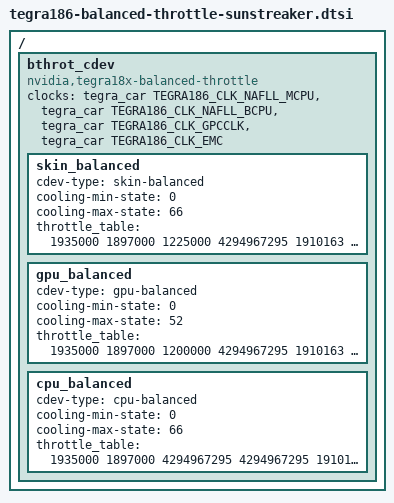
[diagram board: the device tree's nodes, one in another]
/*
 * arch/arm64/boot/dts/tegra186-platforms/tegra186-balanced-throttle-sunstreaker.dtsi
 *
 * Copyright (c) 2016, NVIDIA CORPORATION.  All rights reserved.
 *
 * This program is free software; you can redistribute it and/or modify
 * it under the terms of the GNU General Public License as published by
 * the Free Software Foundation; version 2 of the License.
 *
 * This program is distributed in the hope that it will be useful, but WITHOUT
 * ANY WARRANTY; without even the implied warranty of MERCHANTABILITY or
 * FITNESS FOR A PARTICULAR PURPOSE.  See the GNU General Public License for
 * more details.
 *
 * You should have received a copy of the GNU General Public License along
 * with this program; if not, write to the Free Software Foundation, Inc.,
 * 51 Franklin Street, Fifth Floor, Boston, MA  02110-1301, USA.
 *
 */

/{
	bthrot_cdev {
		compatible = "nvidia,tegra18x-balanced-throttle";
		clocks = <&tegra_car TEGRA186_CLK_NAFLL_MCPU>,
				 <&tegra_car TEGRA186_CLK_NAFLL_BCPU>,
				 <&tegra_car TEGRA186_CLK_GPCCLK>,
				 <&tegra_car TEGRA186_CLK_EMC>;
		clock-names = "mcpu", "bcpu", "gpu", "emc";

		skin_balanced {
			cdev-type = "skin-balanced";
			cooling-min-state = <0>;
			cooling-max-state = <66>;
			#cooling-cells = <2>;
			throttle_table = <
				1935000	1897000	1225000	4294967295
				1910163	1872748	1209454	4294967295
				1885326	1848495	1193908	4294967295
				1860489	1824243	1178362	4294967295
				1835652	1799991	1162815	4294967295
				1810815	1775738	1147269	4294967295
				1785978	1751486	1131723	4294967295
				1761142	1727234	1116177	4294967295
				1736305	1702982	1100631	4294967295
				1711468	1678729	1085085	4294967295
				1686631	1654477	1069538	4294967295
				1661794	1630225	1053992	4294967295
				1636957	1605972	1038446	4294967295
				1612120	1581720	1022900	4294967295
				1587283	1557468	1007354	4294967295
				1562446	1533215	991808	4294967295
				1537609	1508963	976262	4294967295
				1512772	1484711	960715	4294967295
				1487935	1460458	945169	4294967295
				1463098	1436206	929623	4294967295
				1438262	1411954	914077	4294967295
				1413425	1387702	898531	4294967295
				1388588	1363449	882985	4294967295
				1363751	1339197	867438	4294967295
				1338914	1314945	851892	4294967295
				1314077	1290692	836346	4294967295
				1289240	1266440	820800	4294967295
				1264403	1242188	805254	4294967295
				1239566	1217935	789708	4294967295
				1214729	1193683	774162	4294967295
				1189892	1169431	758615	4294967295
				1165055	1145178	743069	4294967295
				1140218	1120926	727523	4294967295
				1115382	1096674	711977	4294967295
				1090545	1072422	696431	4294967295
				1065708	1048169	680885	4294967295
				1040871	1023917	665338	4294967295
				1016034	999665	649792	4294967295
				991197	975412	634246	4294967295
				966360	951160	618700	4294967295
				941523	926908	603154	4294967295
				916686	902655	587608	4294967295
				891849	878403	572062	4294967295
				867012	854151	556515	4294967295
				842175	829898	540969	4294967295
				817338	805646	525423	4294967295
				792502	781394	509877	4294967295
				767665	757142	494331	4294967295
				742828	732889	478785	4294967295
				717991	708637	463238	4294967295
				693154	684385	447692	4294967295
				668317	660132	432146	4294967295
				643480	635880	416600	4294967295
				618643	611628	401054	4294967295
				593806	587375	385508	4294967295
				568969	563123	369962	4294967295
				544132	538871	354415	4294967295
				519295	514618	338869	4294967295
				494458	490366	323323	4294967295
				469622	466114	307777	4294967295
				444785	441862	292231	4294967295
				419948	417609	276685	4294967295
				395111	393357	261138	4294967295
				370274	369105	245592	4294967295
				345437	344852	230046	4294967295
				320600	320600	214500	4294967295
			>;
		};

		gpu_balanced {
			cdev-type = "gpu-balanced";
			cooling-min-state = <0>;
			cooling-max-state = <52>;
			#cooling-cells = <2>;
			throttle_table = <
				1935000	1897000	1200000	4294967295
				1910163	1872748	1180676	4294967295
				1885326	1848495	1161353	4294967295
				1860489	1824243	1142029	4294967295
				1835652	1799991	1122706	4294967295
				1810815	1775738	1103382	4294967295
				1785978	1751486	1084059	4294967295
				1761142	1727234	1064735	4294967295
				1736305	1702982	1045412	4294967295
				1711468	1678729	1026088	4294967295
				1686631	1654477	1006765	4294967295
				1661794	1630225	987441	4294967295
				1636957	1605972	968118	4294967295
				1612120	1581720	948794	4294967295
				1587283	1557468	929471	4294967295
				1562446	1533215	910147	4294967295
				1537609	1508963	890824	4294967295
				1512772	1484711	871500	4294967295
				1487935	1460458	852176	4294967295
				1463098	1436206	832853	4294967295
				1438262	1411954	813529	4294967295
				1413425	1387702	794206	4294967295
				1388588	1363449	774882	4294967295
				1363751	1339197	755559	4294967295
				1338914	1314945	736235	4294967295
				1314077	1290692	716912	4294967295
				1289240	1266440	697588	4294967295
				1264403	1242188	678265	4294967295
				1239566	1217935	658941	4294967295
				1214729	1193683	639618	4294967295
				1189892	1169431	620294	4294967295
				1165055	1145178	600971	4294967295
				1140218	1120926	581647	4294967295
				1115382	1096674	562324	4294967295
				1090545	1072422	543000	4294967295
				1065708	1048169	523676	4294967295
				1040871	1023917	504353	4294967295
				1016034	999665	485029	4294967295
				991197	975412	465706	4294967295
				966360	951160	446382	4294967295
				941523	926908	427059	4294967295
				916686	902655	407735	4294967295
				891849	878403	388412	4294967295
				867012	854151	369088	4294967295
				842175	829898	349765	4294967295
				817338	805646	330441	4294967295
				792502	781394	311118	4294967295
				767665	757142	291794	4294967295
				742828	732889	272471	4294967295
				717991	708637	253147	4294967295
				693154	684385	233824	4294967295
				668317	660132	214500	4294967295
			>;
		};

		cpu_balanced {
			cdev-type = "cpu-balanced";
			cooling-min-state = <0>;
			cooling-max-state = <66>;
			#cooling-cells = <2>;
			throttle_table = <
				1935000	1897000	4294967295	4294967295
				1910163	1872748	4294967295	4294967295
				1885326	1848495	4294967295	4294967295
				1860489	1824243	4294967295	4294967295
				1835652	1799991	4294967295	4294967295
				1810815	1775738	4294967295	4294967295
				1785978	1751486	4294967295	4294967295
				1761142	1727234	4294967295	4294967295
				1736305	1702982	4294967295	4294967295
				1711468	1678729	4294967295	4294967295
				1686631	1654477	1275000	4294967295
				1661794	1630225	1255718	4294967295
				1636957	1605972	1236436	4294967295
				1612120	1581720	1217155	4294967295
				1587283	1557468	1197873	4294967295
				1562446	1533215	1178591	4294967295
				1537609	1508963	1159309	4294967295
				1512772	1484711	1140027	4294967295
				1487935	1460458	1120745	4294967295
				1463098	1436206	1101464	4294967295
				1438262	1411954	1082182	4294967295
				1413425	1387702	1062900	4294967295
				1388588	1363449	1043618	4294967295
				1363751	1339197	1024336	4294967295
				1338914	1314945	1005055	4294967295
				1314077	1290692	985773	4294967295
				1289240	1266440	966491	4294967295
				1264403	1242188	947209	4294967295
				1239566	1217935	927927	4294967295
				1214729	1193683	908645	4294967295
				1189892	1169431	889364	4294967295
				1165055	1145178	870082	4294967295
				1140218	1120926	850800	4294967295
				1115382	1096674	831518	4294967295
				1090545	1072422	812236	4294967295
				1065708	1048169	792955	4294967295
				1040871	1023917	773673	4294967295
				1016034	999665	754391	4294967295
				991197	975412	735109	4294967295
				966360	951160	715827	4294967295
				941523	926908	696545	4294967295
				916686	902655	677264	4294967295
				891849	878403	657982	4294967295
				867012	854151	638700	4294967295
				842175	829898	619418	4294967295
				817338	805646	600136	4294967295
				792502	781394	580855	4294967295
				767665	757142	561573	4294967295
				742828	732889	542291	4294967295
				717991	708637	523009	4294967295
				693154	684385	503727	4294967295
				668317	660132	484445	4294967295
				643480	635880	465164	4294967295
				618643	611628	445882	4294967295
				593806	587375	426600	4294967295
				568969	563123	407318	4294967295
				544132	538871	388036	4294967295
				519295	514618	368755	4294967295
				494458	490366	349473	4294967295
				469622	466114	330191	4294967295
				444785	441862	310909	4294967295
				419948	417609	291627	4294967295
				395111	393357	272345	4294967295
				370274	369105	253064	4294967295
				345437	344852	233782	4294967295
				320600	320600	214500	4294967295
			>;
		};
	};
};

